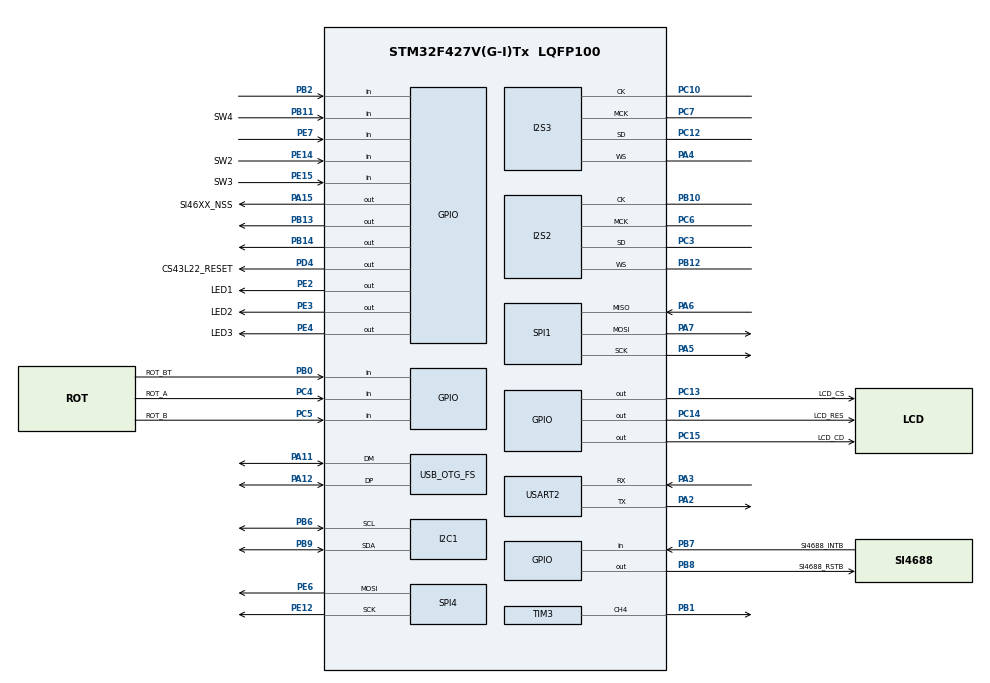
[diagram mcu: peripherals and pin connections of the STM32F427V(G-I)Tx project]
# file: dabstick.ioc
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Dma.Request0=SPI3_TX
Dma.Request1=SPI2_RX
Dma.SPI2_RX.1.Channel=DMA_CHANNEL_0
Dma.SPI2_RX.1.Direction=DMA_PERIPH_TO_MEMORY
Dma.SPI2_RX.1.FIFOMode=DMA_FIFOMODE_DISABLE
Dma.SPI2_RX.1.Instance=DMA1_Stream3
Dma.SPI2_RX.1.MemDataAlignment=DMA_MDATAALIGN_HALFWORD
Dma.SPI2_RX.1.MemInc=DMA_MINC_ENABLE
Dma.SPI2_RX.1.Mode=DMA_NORMAL
Dma.SPI2_RX.1.PeriphDataAlignment=DMA_PDATAALIGN_HALFWORD
Dma.SPI2_RX.1.PeriphInc=DMA_PINC_DISABLE
Dma.SPI2_RX.1.Priority=DMA_PRIORITY_VERY_HIGH
Dma.SPI3_TX.0.Channel=DMA_CHANNEL_0
Dma.SPI3_TX.0.Direction=DMA_MEMORY_TO_PERIPH
Dma.SPI3_TX.0.FIFOMode=DMA_FIFOMODE_DISABLE
Dma.SPI3_TX.0.Instance=DMA1_Stream7
Dma.SPI3_TX.0.MemDataAlignment=DMA_MDATAALIGN_HALFWORD
Dma.SPI3_TX.0.MemInc=DMA_MINC_ENABLE
Dma.SPI3_TX.0.Mode=DMA_NORMAL
Dma.SPI3_TX.0.PeriphDataAlignment=DMA_PDATAALIGN_HALFWORD
Dma.SPI3_TX.0.PeriphInc=DMA_PINC_DISABLE
Dma.SPI3_TX.0.Priority=DMA_PRIORITY_VERY_HIGH
FATFS._FS_LOCK=2
FATFS._FS_READONLY=0
FATFS._MULTI_PARTITION=0
I2S2.AudioFreq-Half_Duplex_Master=I2S_AUDIOFREQ_48K
I2S2.ErrorAudioFreq-Half_Duplex_Master=-0.79 %
I2S2.Mode-Half_Duplex_Master=I2S_MODE_MASTER_RX
I2S2.RealAudioFreq-Half_Duplex_Master=47.619 KHz
I2S3.AudioFreq-Half_Duplex_Master=I2S_AUDIOFREQ_48K
I2S3.ErrorAudioFreq-Half_Duplex_Master=-0.79 %
I2S3.RealAudioFreq-Half_Duplex_Master=47.619 KHz
Mcu.Family=STM32F4
Mcu.Name=STM32F427V(G-I)Tx
Mcu.Package=LQFP100
NVIC.DMA1_Stream3_IRQn=true\:0\:0
NVIC.DMA1_Stream7_IRQn=true\:0\:1
NVIC.OTG_FS_IRQn=true\:0\:0
NVIC.PriorityGroup=NVIC_PRIORITYGROUP_0
PA11.Mode=Device_Only
PA11.Signal=USB_OTG_FS_DM
PA12.Mode=Device_Only
PA12.Signal=USB_OTG_FS_DP
PA13.Mode=Trace-Asynchronous_SW
PA13.Signal=SYS_JTMS-SWDIO
PA14.Mode=Trace-Asynchronous_SW
PA14.Signal=SYS_JTCK-SWCLK
PA15.GPIO_Label=SI46XX_NSS
PA15.GPIO_ModeDefaultOutputPP=GPIO_MODE_OUTPUT_PP
PA15.GPIO_PuPd=GPIO_NOPULL
PA15.GPIO_Speed=GPIO_SPEED_LOW
PA15.Signal=GPIO_Output
PA2.Mode=Asynchronous
PA2.Signal=USART2_TX
PA3.GPIO_Mode=GPIO_MODE_AF_PP
PA3.GPIO_PuPd=GPIO_PULLDOWN
PA3.GPIO_Speed=GPIO_SPEED_LOW
PA3.Mode=Asynchronous
PA3.Signal=USART2_RX
PA4.Mode=Half_Duplex_Master
PA4.Signal=I2S3_WS
PA5.Mode=Full_Duplex_Master
PA5.Signal=SPI1_SCK
PA6.Mode=Full_Duplex_Master
PA6.Signal=SPI1_MISO
PA7.Mode=Full_Duplex_Master
PA7.Signal=SPI1_MOSI
PB0.GPIO_Label=ROT_BT
PB0.GPIO_Mode=GPIO_MODE_INPUT
PB0.GPIO_PuPd=GPIO_PULLUP
PB0.Signal=GPIO_Input
PB1.Signal=S_TIM3_CH4
PB10.Mode=Half_Duplex_Master
PB10.Signal=I2S2_CK
PB11.GPIO_Label=SW4
PB11.GPIO_Mode=GPIO_MODE_INPUT
PB11.GPIO_PuPd=GPIO_PULLUP
PB11.Signal=GPIO_Input
PB12.Mode=Half_Duplex_Master
PB12.Signal=I2S2_WS
PB13.Signal=GPIO_Output
PB14.Signal=GPIO_Output
PB2/BOOT1.GPIO_Mode=GPIO_MODE_INPUT
PB2/BOOT1.GPIO_PuPd=GPIO_PULLUP
PB2/BOOT1.Signal=GPIO_Input
PB3.Mode=Trace-Asynchronous_SW
PB3.Signal=SYS_JTDO-SWO
PB6.GPIO_Mode=GPIO_MODE_AF_OD
PB6.GPIO_PuPd=GPIO_PULLUP
PB6.GPIO_Speed=GPIO_SPEED_LOW
PB6.Mode=I2C
PB6.Signal=I2C1_SCL
PB7.GPIO_Label=SI4688_INTB
PB7.GPIO_Mode=GPIO_MODE_INPUT
PB7.GPIO_PuPd=GPIO_PULLUP
PB7.Signal=GPIO_Input
PB8.GPIO_Label=SI4688_RSTB
PB8.GPIO_ModeDefaultOutputPP=GPIO_MODE_OUTPUT_PP
PB8.GPIO_PuPd=GPIO_NOPULL
PB8.GPIO_Speed=GPIO_SPEED_LOW
PB8.Signal=GPIO_Output
PB9.GPIO_Mode=GPIO_MODE_AF_OD
PB9.GPIO_PuPd=GPIO_PULLUP
PB9.GPIO_Speed=GPIO_SPEED_LOW
PB9.Mode=I2C
PB9.Signal=I2C1_SDA
PC10.Mode=Half_Duplex_Master
PC10.Signal=I2S3_CK
PC12.Mode=Half_Duplex_Master
PC12.Signal=I2S3_SD
PC13.GPIO_Label=LCD_CS
PC13.GPIO_ModeDefaultOutputPP=GPIO_MODE_OUTPUT_PP
PC13.GPIO_PuPd=GPIO_NOPULL
PC13.GPIO_Speed=GPIO_SPEED_LOW
PC13.Signal=GPIO_Output
PC14/OSC32_IN.GPIO_Label=LCD_RES
PC14/OSC32_IN.GPIO_ModeDefaultOutputPP=GPIO_MODE_OUTPUT_PP
PC14/OSC32_IN.GPIO_PuPd=GPIO_NOPULL
PC14/OSC32_IN.GPIO_Speed=GPIO_SPEED_LOW
PC14/OSC32_IN.Signal=GPIO_Output
PC15/OSC32_OUT.GPIO_Label=LCD_CD
PC15/OSC32_OUT.GPIO_ModeDefaultOutputPP=GPIO_MODE_OUTPUT_PP
PC15/OSC32_OUT.GPIO_PuPd=GPIO_NOPULL
PC15/OSC32_OUT.GPIO_Speed=GPIO_SPEED_LOW
PC15/OSC32_OUT.Signal=GPIO_Output
PC3.Mode=Half_Duplex_Master
PC3.Signal=I2S2_SD
PC4.GPIO_Label=ROT_A
PC4.GPIO_Mode=GPIO_MODE_INPUT
PC4.GPIO_PuPd=GPIO_PULLUP
PC4.Signal=GPIO_Input
PC5.GPIO_Label=ROT_B
PC5.GPIO_Mode=GPIO_MODE_INPUT
PC5.GPIO_PuPd=GPIO_PULLUP
PC5.Signal=GPIO_Input
PC6.Mode=Master_Clock_Activated
PC6.Signal=I2S2_MCK
PC7.GPIO_Mode=GPIO_MODE_AF_PP
PC7.GPIO_PuPd=GPIO_NOPULL
PC7.GPIO_Speed=GPIO_SPEED_FAST
PC7.Mode=Master_Clock_Activated
PC7.Signal=I2S3_MCK
PD4.GPIO_Label=CS43L22_RESET
PD4.GPIO_ModeDefaultOutputPP=GPIO_MODE_OUTPUT_PP
PD4.GPIO_PuPd=GPIO_NOPULL
PD4.GPIO_Speed=GPIO_SPEED_LOW
PD4.Signal=GPIO_Output
PE12.Mode=TX_Only_Simplex_Unidirect_Master
PE12.Signal=SPI4_SCK
PE14.GPIO_Label=SW2
PE14.GPIO_Mode=GPIO_MODE_INPUT
PE14.GPIO_PuPd=GPIO_PULLUP
PE14.Signal=GPIO_Input
PE15.GPIO_Label=SW3
PE15.GPIO_Mode=GPIO_MODE_INPUT
PE15.GPIO_PuPd=GPIO_PULLUP
PE15.Signal=GPIO_Input
PE2.GPIO_Label=LED1
PE2.GPIO_ModeDefaultOutputPP=GPIO_MODE_OUTPUT_PP
PE2.GPIO_PuPd=GPIO_NOPULL
PE2.GPIO_Speed=GPIO_SPEED_LOW
PE2.Signal=GPIO_Output
PE3.GPIO_Label=LED2
PE3.GPIO_ModeDefaultOutputPP=GPIO_MODE_OUTPUT_PP
PE3.GPIO_PuPd=GPIO_NOPULL
PE3.GPIO_Speed=GPIO_SPEED_LOW
PE3.Signal=GPIO_Output
PE4.GPIO_Label=LED3
PE4.GPIO_ModeDefaultOutputPP=GPIO_MODE_OUTPUT_PP
PE4.GPIO_PuPd=GPIO_NOPULL
PE4.GPIO_Speed=GPIO_SPEED_LOW
PE4.Signal=GPIO_Output
PE6.Mode=TX_Only_Simplex_Unidirect_Master
PE6.Signal=SPI4_MOSI
PE7.GPIO_Mode=GPIO_MODE_INPUT
PE7.GPIO_PuPd=GPIO_PULLUP
PE7.Signal=GPIO_Input
PH0/OSC_IN.Mode=HSE-External-Oscillator
PH0/OSC_IN.Signal=RCC_OSC_IN
PH1/OSC_OUT.Mode=HSE-External-Oscillator
PH1/OSC_OUT.Signal=RCC_OSC_OUT
ProjectManager.TargetToolchain=TrueSTUDIO 4.3.1
RCC.APB1CLKDivider=RCC_HCLK_DIV4
RCC.APB2CLKDivider=RCC_HCLK_DIV2
RCC.HSE_VALUE=8000000
RCC.HSI_VALUE=16000000
RCC.LSE_VALUE=32768
RCC.PLLM=8
RCC.PLLN=336
RCC.PLLQ=7
RCC.PLLSource=RCC_PLLSOURCE_HSE
RCC.SYSCLKSource=RCC_SYSCLKSOURCE_PLLCLK
SH.S_TIM3_CH4.0=TIM3_CH4,PWM Generation4 CH4
SPI1.BaudRatePrescaler-Full_Duplex_Master=SPI_BAUDRATEPRESCALER_16
SPI1.CalculateBaudRate-Full_Duplex_Master=5.25 MBits/s
SPI1.Mode-Full_Duplex_Master=SPI_MODE_MASTER
SPI4.BaudRatePrescaler-TX_Only_Simplex_Unidirect_Master=SPI_BAUDRATEPRESCALER_16
SPI4.CalculateBaudRate-TX_Only_Simplex_Unidirect_Master=5.25 MBits/s
SPI4.Mode-TX_Only_Simplex_Unidirect_Master=SPI_MODE_MASTER
TIM3.Channel-PWM\ Generation4\ CH4=TIM_CHANNEL_4
TIM3.Period=1024
TIM3.Prescaler=32
TIM3.Pulse-PWM\ Generation4\ CH4=512
USB_DEVICE.USBD_DEBUG_LEVEL=3
USB_DEVICE.USBD_HandleTypeDef=hUsbDeviceFS
USB_DEVICE.VirtualMode=Msc
USB_DEVICE.VirtualModeFS=Msc_FS
USB_OTG_FS.VirtualMode-Device_Only=Device_Only
VP_FATFS_VS_Generic.Mode=User-defined
VP_TIM3_VS_ClockSourceINT.Mode=Internal
VP_USB_DEVICE_VS_USB_DEVICE_MSC_FS.Mode=MSC_FS

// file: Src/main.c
/**
  ******************************************************************************
  * File Name          : main.c
  * Date               : 07/09/2014 10:33:22
  * Description        : Main program body
  ******************************************************************************
  *
  * COPYRIGHT(c) 2014 STMicroelectronics
  *
  * Redistribution and use in source and binary forms, with or without modification,
  * are permitted provided that the following conditions are met:
  *   1. Redistributions of source code must retain the above copyright notice,
  *      this list of conditions and the following disclaimer.
  *   2. Redistributions in binary form must reproduce the above copyright notice,
  *      this list of conditions and the following disclaimer in the documentation
  *      and/or other materials provided with the distribution.
  *   3. Neither the name of STMicroelectronics nor the names of its contributors
  *      may be used to endorse or promote products derived from this software
  *      without specific prior written permission.
  *
  * THIS SOFTWARE IS PROVIDED BY THE COPYRIGHT HOLDERS AND CONTRIBUTORS "AS IS"
  * AND ANY EXPRESS OR IMPLIED WARRANTIES, INCLUDING, BUT NOT LIMITED TO, THE
  * IMPLIED WARRANTIES OF MERCHANTABILITY AND FITNESS FOR A PARTICULAR PURPOSE ARE
  * DISCLAIMED. IN NO EVENT SHALL THE COPYRIGHT HOLDER OR CONTRIBUTORS BE LIABLE
  * FOR ANY DIRECT, INDIRECT, INCIDENTAL, SPECIAL, EXEMPLARY, OR CONSEQUENTIAL
  * DAMAGES (INCLUDING, BUT NOT LIMITED TO, PROCUREMENT OF SUBSTITUTE GOODS OR
  * SERVICES; LOSS OF USE, DATA, OR PROFITS; OR BUSINESS INTERRUPTION) HOWEVER
  * CAUSED AND ON ANY THEORY OF LIABILITY, WHETHER IN CONTRACT, STRICT LIABILITY,
  * OR TORT (INCLUDING NEGLIGENCE OR OTHERWISE) ARISING IN ANY WAY OUT OF THE USE
  * OF THIS SOFTWARE, EVEN IF ADVISED OF THE POSSIBILITY OF SUCH DAMAGE.
  *
  ******************************************************************************
  */

#include "stm32f4xx_hal.h"
#include "ff.h"
#include "ff_gen_drv.h"
#include "user_diskio.h" /* defines USER_Driver as external */
#include "usb_device.h"

I2C_HandleTypeDef hi2c1;

I2S_HandleTypeDef hi2s2;
I2S_HandleTypeDef hi2s3;
DMA_HandleTypeDef hdma_spi2_rx;
DMA_HandleTypeDef hdma_spi3_tx;

SPI_HandleTypeDef hspi1;
SPI_HandleTypeDef hspi4;

TIM_HandleTypeDef htim3;

UART_HandleTypeDef huart2;

uint8_t USER_DriverNum;      /* FatFS USER part */
char USER_Path[4];           /* USER logical drive path */

/* USER CODE BEGIN 0 */
#include "dabstick.h"

/* USER CODE END 0 */

void SystemClock_Config(void);
static void MX_GPIO_Init(void);
static void MX_DMA_Init(void);
static void MX_I2C1_Init(void);
static void MX_I2S2_Init(void);
static void MX_I2S3_Init(void);
static void MX_SPI1_Init(void);
static void MX_SPI4_Init(void);
static void MX_TIM3_Init(void);
static void MX_USART2_UART_Init(void);

int main(void)
{

  /* MCU Configuration----------------------------------------------------------*/

  /* Reset of all peripherals, Initializes the Flash interface and the Systick. */
  HAL_Init();

  /* Configure the system clock */
  SystemClock_Config();

  /* System interrupt init*/
  /* Sets the priority grouping field */
  HAL_NVIC_SetPriorityGrouping(NVIC_PRIORITYGROUP_0);
  HAL_NVIC_SetPriority(SysTick_IRQn, 0, 0);

  /* Initialize all configured peripherals */
  MX_GPIO_Init();
  MX_DMA_Init();
  MX_I2C1_Init();
  MX_I2S2_Init();
  MX_I2S3_Init();
  MX_SPI1_Init();
  MX_SPI4_Init();
  MX_TIM3_Init();
  MX_USART2_UART_Init();
  MX_USB_DEVICE_Init();

  /*## FatFS: Link the USER disk I/O driver ###############################*/
  USER_DriverNum = FATFS_LinkDriver(&USER_Driver, USER_Path);

  /* USER CODE BEGIN 3 */
  dabstick_loop(); // endless
  return 0;
  /* USER CODE END 3 */

}

/** System Clock Configuration
*/
void SystemClock_Config(void)
{

  RCC_ClkInitTypeDef RCC_ClkInitStruct;
  RCC_PeriphCLKInitTypeDef PeriphClkInitStruct;
  RCC_OscInitTypeDef RCC_OscInitStruct;

  __PWR_CLK_ENABLE();

  __HAL_PWR_VOLTAGESCALING_CONFIG(PWR_REGULATOR_VOLTAGE_SCALE1);

  RCC_OscInitStruct.OscillatorType = RCC_OSCILLATORTYPE_HSE;
  RCC_OscInitStruct.HSEState = RCC_HSE_ON;
  RCC_OscInitStruct.PLL.PLLState = RCC_PLL_ON;
  RCC_OscInitStruct.PLL.PLLSource = RCC_PLLSOURCE_HSE;
  RCC_OscInitStruct.PLL.PLLM = 8;
  RCC_OscInitStruct.PLL.PLLN = 336;
  RCC_OscInitStruct.PLL.PLLP = RCC_PLLP_DIV2;
  RCC_OscInitStruct.PLL.PLLQ = 7;
  HAL_RCC_OscConfig(&RCC_OscInitStruct);

  RCC_ClkInitStruct.ClockType = RCC_CLOCKTYPE_SYSCLK|RCC_CLOCKTYPE_PCLK1
                              |RCC_CLOCKTYPE_PCLK2;
  RCC_ClkInitStruct.SYSCLKSource = RCC_SYSCLKSOURCE_PLLCLK;
  RCC_ClkInitStruct.AHBCLKDivider = RCC_SYSCLK_DIV1;
  RCC_ClkInitStruct.APB1CLKDivider = RCC_HCLK_DIV4;
  RCC_ClkInitStruct.APB2CLKDivider = RCC_HCLK_DIV2;
  HAL_RCC_ClockConfig(&RCC_ClkInitStruct, FLASH_LATENCY_5);

  PeriphClkInitStruct.PeriphClockSelection = RCC_PERIPHCLK_I2S;
  PeriphClkInitStruct.PLLI2S.PLLI2SN = 192;
  PeriphClkInitStruct.PLLI2S.PLLI2SR = 2;
  HAL_RCCEx_PeriphCLKConfig(&PeriphClkInitStruct);

}

/* I2C1 init function */
void MX_I2C1_Init(void)
{

  hi2c1.Instance = I2C1;
  hi2c1.Init.ClockSpeed = 100000;
  hi2c1.Init.DutyCycle = I2C_DUTYCYCLE_2;
  hi2c1.Init.OwnAddress1 = 0;
  hi2c1.Init.AddressingMode = I2C_ADDRESSINGMODE_7BIT;
  hi2c1.Init.DualAddressMode = I2C_DUALADDRESS_DISABLED;
  hi2c1.Init.OwnAddress2 = 0;
  hi2c1.Init.GeneralCallMode = I2C_GENERALCALL_DISABLED;
  hi2c1.Init.NoStretchMode = I2C_NOSTRETCH_DISABLED;
  HAL_I2C_Init(&hi2c1);

}

/* I2S2 init function */
void MX_I2S2_Init(void)
{

  hi2s2.Instance = SPI2;
  hi2s2.Init.Mode = I2S_MODE_MASTER_RX;
  hi2s2.Init.Standard = I2S_STANDARD_PHILLIPS;
  hi2s2.Init.DataFormat = I2S_DATAFORMAT_16B;
  hi2s2.Init.MCLKOutput = I2S_MCLKOUTPUT_ENABLE;
  hi2s2.Init.AudioFreq = I2S_AUDIOFREQ_48K;
  hi2s2.Init.CPOL = I2S_CPOL_LOW;
  hi2s2.Init.ClockSource = I2S_CLOCK_PLL;
  hi2s2.Init.FullDuplexMode = I2S_FULLDUPLEXMODE_DISABLE;
  HAL_I2S_Init(&hi2s2);

}

/* I2S3 init function */
void MX_I2S3_Init(void)
{

  hi2s3.Instance = SPI3;
  hi2s3.Init.Mode = I2S_MODE_MASTER_TX;
  hi2s3.Init.Standard = I2S_STANDARD_PHILLIPS;
  hi2s3.Init.DataFormat = I2S_DATAFORMAT_16B;
  hi2s3.Init.MCLKOutput = I2S_MCLKOUTPUT_ENABLE;
  hi2s3.Init.AudioFreq = I2S_AUDIOFREQ_48K;
  hi2s3.Init.CPOL = I2S_CPOL_LOW;
  hi2s3.Init.ClockSource = I2S_CLOCK_PLL;
  hi2s3.Init.FullDuplexMode = I2S_FULLDUPLEXMODE_DISABLE;
  HAL_I2S_Init(&hi2s3);

}

/* SPI1 init function */
void MX_SPI1_Init(void)
{

  hspi1.Instance = SPI1;
  hspi1.Init.Mode = SPI_MODE_MASTER;
  hspi1.Init.Direction = SPI_DIRECTION_2LINES;
  hspi1.Init.DataSize = SPI_DATASIZE_8BIT;
  hspi1.Init.CLKPolarity = SPI_POLARITY_LOW;
  hspi1.Init.CLKPhase = SPI_PHASE_1EDGE;
  hspi1.Init.NSS = SPI_NSS_SOFT;
  hspi1.Init.BaudRatePrescaler = SPI_BAUDRATEPRESCALER_16;
  hspi1.Init.FirstBit = SPI_FIRSTBIT_MSB;
  hspi1.Init.TIMode = SPI_TIMODE_DISABLED;
  hspi1.Init.CRCCalculation = SPI_CRCCALCULATION_DISABLED;
  HAL_SPI_Init(&hspi1);

}

/* SPI4 init function */
void MX_SPI4_Init(void)
{

  hspi4.Instance = SPI4;
  hspi4.Init.Mode = SPI_MODE_MASTER;
  hspi4.Init.Direction = SPI_DIRECTION_2LINES;
  hspi4.Init.DataSize = SPI_DATASIZE_8BIT;
  hspi4.Init.CLKPolarity = SPI_POLARITY_LOW;
  hspi4.Init.CLKPhase = SPI_PHASE_1EDGE;
  hspi4.Init.NSS = SPI_NSS_SOFT;
  hspi4.Init.BaudRatePrescaler = SPI_BAUDRATEPRESCALER_16;
  hspi4.Init.FirstBit = SPI_FIRSTBIT_MSB;
  hspi4.Init.TIMode = SPI_TIMODE_DISABLED;
  hspi4.Init.CRCCalculation = SPI_CRCCALCULATION_DISABLED;
  HAL_SPI_Init(&hspi4);

}

/* TIM3 init function */
void MX_TIM3_Init(void)
{

  TIM_ClockConfigTypeDef sClockSourceConfig;
  TIM_OC_InitTypeDef sConfigOC;
  TIM_MasterConfigTypeDef sMasterConfig;

  htim3.Instance = TIM3;
  htim3.Init.Prescaler = 32;
  htim3.Init.CounterMode = TIM_COUNTERMODE_UP;
  htim3.Init.Period = 1024;
  htim3.Init.ClockDivision = TIM_CLOCKDIVISION_DIV1;
  HAL_TIM_Base_Init(&htim3);

  sClockSourceConfig.ClockSource = TIM_CLOCKSOURCE_INTERNAL;
  HAL_TIM_ConfigClockSource(&htim3, &sClockSourceConfig);

  HAL_TIM_PWM_Init(&htim3);

  sConfigOC.OCMode = TIM_OCMODE_PWM1;
  sConfigOC.Pulse = 512;
  sConfigOC.OCPolarity = TIM_OCPOLARITY_HIGH;
  sConfigOC.OCFastMode = TIM_OCFAST_DISABLE;
  HAL_TIM_PWM_ConfigChannel(&htim3, &sConfigOC, TIM_CHANNEL_4);

  sMasterConfig.MasterOutputTrigger = TIM_TRGO_RESET;
  sMasterConfig.MasterSlaveMode = TIM_MASTERSLAVEMODE_DISABLE;
  HAL_TIMEx_MasterConfigSynchronization(&htim3, &sMasterConfig);

}

/* USART2 init function */
void MX_USART2_UART_Init(void)
{

  huart2.Instance = USART2;
  huart2.Init.BaudRate = 115200;
  huart2.Init.WordLength = UART_WORDLENGTH_8B;
  huart2.Init.StopBits = UART_STOPBITS_1;
  huart2.Init.Parity = UART_PARITY_NONE;
  huart2.Init.Mode = UART_MODE_TX_RX;
  huart2.Init.HwFlowCtl = UART_HWCONTROL_NONE;
  huart2.Init.OverSampling = UART_OVERSAMPLING_16;
  HAL_UART_Init(&huart2);

}

void MX_DMA_Init(void)
{
  /* DMA controller clock enable */
  __DMA1_CLK_ENABLE();

  /* DMA interrupt init */
  /* Sets the priority grouping field */
  HAL_NVIC_SetPriorityGrouping(NVIC_PRIORITYGROUP_0);
  HAL_NVIC_SetPriority(DMA1_Stream3_IRQn, 0, 0);
  HAL_NVIC_EnableIRQ(DMA1_Stream3_IRQn);
  /* Sets the priority grouping field */
  HAL_NVIC_SetPriorityGrouping(NVIC_PRIORITYGROUP_0);
  HAL_NVIC_SetPriority(DMA1_Stream7_IRQn, 0, 1);
  HAL_NVIC_EnableIRQ(DMA1_Stream7_IRQn);

}

/** Configure pins as
        * Analog
        * Input
        * Output
        * EVENT_OUT
        * EXTI
*/
void MX_GPIO_Init(void)
{

  GPIO_InitTypeDef GPIO_InitStruct;

  /* GPIO Ports Clock Enable */
  __GPIOE_CLK_ENABLE();
  __GPIOC_CLK_ENABLE();
  __GPIOH_CLK_ENABLE();
  __GPIOA_CLK_ENABLE();
  __GPIOB_CLK_ENABLE();
  __GPIOD_CLK_ENABLE();

  /*Configure GPIO pins : PE2 PE3 PE4 */
  GPIO_InitStruct.Pin = GPIO_PIN_2|GPIO_PIN_3|GPIO_PIN_4;
  GPIO_InitStruct.Mode = GPIO_MODE_OUTPUT_PP;
  GPIO_InitStruct.Pull = GPIO_NOPULL;
  GPIO_InitStruct.Speed = GPIO_SPEED_LOW;
  HAL_GPIO_Init(GPIOE, &GPIO_InitStruct);

  /*Configure GPIO pins : PC13 PC14 PC15 */
  GPIO_InitStruct.Pin = GPIO_PIN_13|GPIO_PIN_14|GPIO_PIN_15;
  GPIO_InitStruct.Mode = GPIO_MODE_OUTPUT_PP;
  GPIO_InitStruct.Pull = GPIO_NOPULL;
  GPIO_InitStruct.Speed = GPIO_SPEED_LOW;
  HAL_GPIO_Init(GPIOC, &GPIO_InitStruct);

  /*Configure GPIO pins : PC4 PC5 */
  GPIO_InitStruct.Pin = GPIO_PIN_4|GPIO_PIN_5;
  GPIO_InitStruct.Mode = GPIO_MODE_INPUT;
  GPIO_InitStruct.Pull = GPIO_PULLUP;
  HAL_GPIO_Init(GPIOC, &GPIO_InitStruct);

  /*Configure GPIO pins : PB0 PB2 PB11 PB7 */
  GPIO_InitStruct.Pin = GPIO_PIN_0|GPIO_PIN_2|GPIO_PIN_11|GPIO_PIN_7;
  GPIO_InitStruct.Mode = GPIO_MODE_INPUT;
  GPIO_InitStruct.Pull = GPIO_PULLUP;
  HAL_GPIO_Init(GPIOB, &GPIO_InitStruct);

  /*Configure GPIO pins : PE7 PE14 PE15 */
  GPIO_InitStruct.Pin = GPIO_PIN_7|GPIO_PIN_14|GPIO_PIN_15;
  GPIO_InitStruct.Mode = GPIO_MODE_INPUT;
  GPIO_InitStruct.Pull = GPIO_PULLUP;
  HAL_GPIO_Init(GPIOE, &GPIO_InitStruct);

  /*Configure GPIO pins : PB13 PB14 PB8 */
  GPIO_InitStruct.Pin = GPIO_PIN_13|GPIO_PIN_14|GPIO_PIN_8;
  GPIO_InitStruct.Mode = GPIO_MODE_OUTPUT_PP;
  GPIO_InitStruct.Pull = GPIO_NOPULL;
  GPIO_InitStruct.Speed = GPIO_SPEED_LOW;
  HAL_GPIO_Init(GPIOB, &GPIO_InitStruct);

  /*Configure GPIO pin : PA15 */
  GPIO_InitStruct.Pin = GPIO_PIN_15;
  GPIO_InitStruct.Mode = GPIO_MODE_OUTPUT_PP;
  GPIO_InitStruct.Pull = GPIO_NOPULL;
  GPIO_InitStruct.Speed = GPIO_SPEED_LOW;
  HAL_GPIO_Init(GPIOA, &GPIO_InitStruct);

  /*Configure GPIO pin : PD4 */
  GPIO_InitStruct.Pin = GPIO_PIN_4;
  GPIO_InitStruct.Mode = GPIO_MODE_OUTPUT_PP;
  GPIO_InitStruct.Pull = GPIO_NOPULL;
  GPIO_InitStruct.Speed = GPIO_SPEED_LOW;
  HAL_GPIO_Init(GPIOD, &GPIO_InitStruct);

}

/************************ (C) COPYRIGHT STMicroelectronics *****END OF FILE****/
